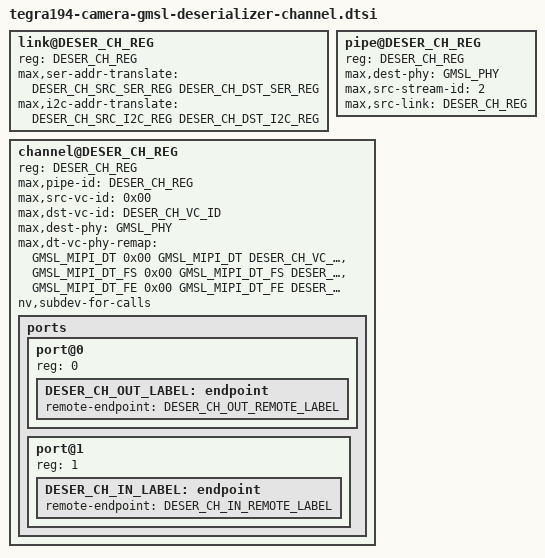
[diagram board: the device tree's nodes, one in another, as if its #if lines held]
#ifdef DESER_CH_INDEX
#define DESER_CH_REG DESER_CH_INDEX
#define DESER_CH_VC_ID DESER_CH_INDEX
#define DESER_CH_OUT_LABEL CONCAT(deser_out, DESER_CH_INDEX)
#define DESER_CH_IN_LABEL CONCAT(deser_in, DESER_CH_INDEX)
#define DESER_CH_OUT_REMOTE_LABEL CONCAT(csi_in, DESER_CH_INDEX)
#define DESER_CH_IN_REMOTE_LABEL CONCAT(ser_out, DESER_CH_INDEX)
#endif

#if !defined(DESER_CH_REG)
#error
#endif

#if !defined(DESER_CH_VC_ID)
#error
#endif

#if !defined(DESER_CH_OUT_LABEL)
#error
#endif

#if !defined(DESER_CH_IN_LABEL)
#error
#endif

#if !defined(DESER_CH_OUT_REMOTE_LABEL)
#error
#endif

#if !defined(DESER_CH_IN_REMOTE_LABEL)
#error
#endif

link@DESER_CH_REG {
	reg = <DESER_CH_REG>;

#if defined(DESER_CH_SRC_SER_REG) && defined(DESER_CH_DST_SER_REG)
	max,ser-addr-translate = <DESER_CH_SRC_SER_REG DESER_CH_DST_SER_REG>;
#endif
#if defined(DESER_CH_SRC_I2C_REG) && defined(DESER_CH_DST_I2C_REG)
	max,i2c-addr-translate = <DESER_CH_SRC_I2C_REG DESER_CH_DST_I2C_REG>;
#endif
};

pipe@DESER_CH_REG {
	reg = <DESER_CH_REG>;

	max,dest-phy = <GMSL_PHY>;
	max,src-stream-id = <2>;
	max,src-link = <DESER_CH_REG>;
};

channel@DESER_CH_REG {
	reg = <DESER_CH_REG>;

	max,pipe-id = <DESER_CH_REG>;
	max,src-vc-id = <0x00>;
	max,dst-vc-id = <DESER_CH_VC_ID>;
	max,dest-phy = <GMSL_PHY>;
	max,dt-vc-phy-remap =
		<GMSL_MIPI_DT 0x00 GMSL_MIPI_DT DESER_CH_VC_ID GMSL_PHY>,
		<GMSL_MIPI_DT_FS 0x00 GMSL_MIPI_DT_FS DESER_CH_VC_ID GMSL_PHY>,
		<GMSL_MIPI_DT_FE 0x00 GMSL_MIPI_DT_FE DESER_CH_VC_ID GMSL_PHY>;

	nv,subdev-for-calls;

	ports {
		#address-cells = <1>;
		#size-cells = <0>;

		port@0 {
			reg = <0>;

			DESER_CH_OUT_LABEL: endpoint {
				remote-endpoint = <&DESER_CH_OUT_REMOTE_LABEL>;
			};
		};

		port@1 {
			reg = <1>;

			DESER_CH_IN_LABEL: endpoint {
				remote-endpoint = <&DESER_CH_IN_REMOTE_LABEL>;
			};
		};
	};
};

#undef DESER_CH_SRC_SER_REG
#undef DESER_CH_DST_SER_REG
#undef DESER_CH_SRC_I2C_REG
#undef DESER_CH_DST_I2C_REG
#undef DESER_CH_INDEX
#undef DESER_CH_REG
#undef DESER_CH_VC_ID
#undef DESER_CH_OUT_LABEL
#undef DESER_CH_IN_LABEL
#undef DESER_CH_OUT_REMOTE_LABEL
#undef DESER_CH_IN_REMOTE_LABEL
